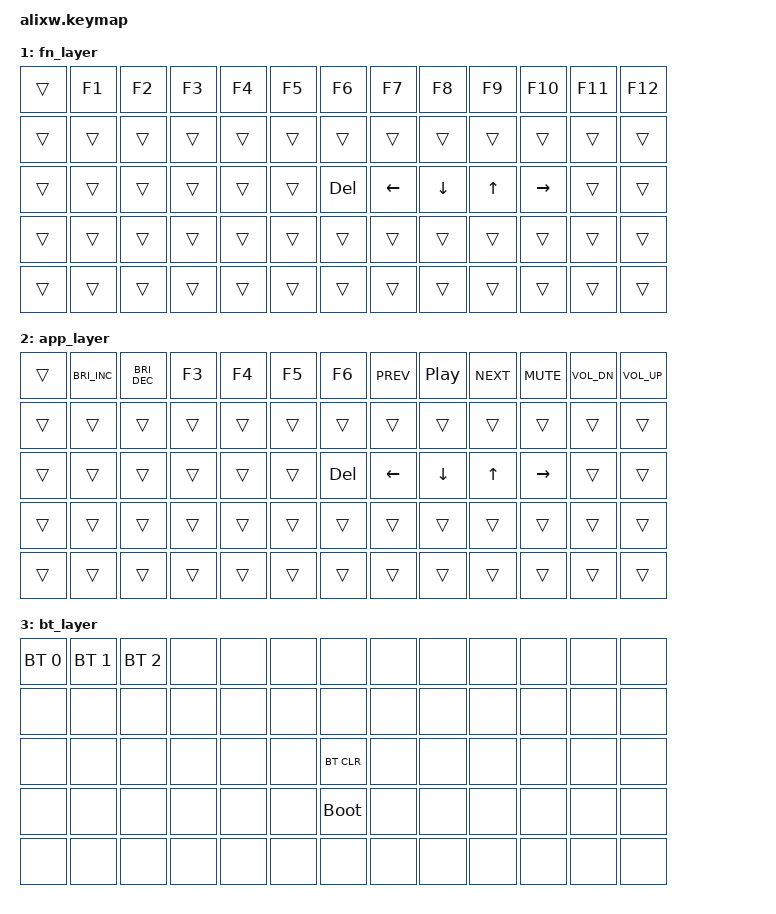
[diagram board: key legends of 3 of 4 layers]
#include <behaviors.dtsi>
#include <dt-bindings/zmk/keys.h>
#include <dt-bindings/zmk/bt.h>

/ {
    keymap {
        compatible = "zmk,keymap";

        default_layer {
            bindings = <
                &kp GRAVE  &kp N1    &kp N2    &kp N3     &kp N4  &kp N5     &kp N6    &kp N7    &kp N8    &kp N9     &kp N0   &kp MINUS  &kp EQUAL
                &kp TAB    &kp Q     &kp W     &kp E      &kp R   &kp T      &kp Y     &kp U     &kp I     &kp O      &kp P    &kp LBKT   &kp RBKT
                &kp CAPS   &kp A     &kp S     &kp D      &kp F   &kp G      &kp BSPC  &kp H     &kp J     &kp K      &kp L    &kp SEMI   &kp SQT
                &kp LSHFT  &kp Z     &kp X     &kp C      &kp V   &kp B      &kp ESC   &kp N     &kp M     &kp COMMA  &kp DOT  &kp SLASH  &kp RSHFT
                &kp LCTRL  &kp LALT  &kp LGUI  &kp SPACE  &mo 2   &kp ENTER  &mo 1     &kp RGUI  &kp RALT  &kp RCTRL  &tog 1   &mo 3      &kp BSLH
            >;
        };

        fn_layer {
            bindings = <
                &trans     &kp F1    &kp F2    &kp F3     &kp F4  &kp F5     &kp F6    &kp F7    &kp F8    &kp F9     &kp F10    &kp F11  &kp F12
                &trans     &trans    &trans    &trans     &trans  &trans     &trans    &trans    &trans    &trans     &trans     &trans   &trans
                &trans     &trans    &trans    &trans     &trans  &trans     &kp DEL   &kp LEFT  &kp DOWN  &kp UP     &kp RIGHT  &trans   &trans
                &trans     &trans    &trans    &trans     &trans  &trans     &trans    &trans    &trans    &trans     &trans     &trans   &trans
                &trans     &trans    &trans    &trans     &trans  &trans     &trans    &trans    &trans    &trans     &trans     &trans   &trans 
            >;
        };

        app_layer {
            bindings = <
                &trans  &kp C_BRI_INC  &kp C_BRI_DEC  &kp F3  &kp F4  &kp F5  &kp F6   &kp C_PREV  &kp C_PP  &kp C_NEXT  &kp K_MUTE  &kp C_VOL_DN  &kp C_VOL_UP
                &trans  &trans         &trans         &trans  &trans  &trans  &trans   &trans      &trans    &trans      &trans      &trans        &trans
                &trans  &trans         &trans         &trans  &trans  &trans  &kp DEL  &kp LEFT    &kp DOWN  &kp UP      &kp RIGHT   &trans        &trans
                &trans  &trans         &trans         &trans  &trans  &trans  &trans   &trans      &trans    &trans      &trans      &trans        &trans
                &trans  &trans         &trans         &trans  &trans  &trans  &trans   &trans      &trans    &trans      &trans      &trans        &trans 
            >;
        };

        bt_layer {
            bindings = <
                &bt BT_SEL 0  &bt BT_SEL 1  &bt BT_SEL 2  &none  &none  &none  &none        &none  &none  &none  &none  &none  &none
                &none         &none         &none         &none  &none  &none  &none        &none  &none  &none  &none  &none  &none
                &none         &none         &none         &none  &none  &none  &bt BT_CLR   &none  &none  &none  &none  &none  &none
                &none         &none         &none         &none  &none  &none  &bootloader  &none  &none  &none  &none  &none  &none
                &none         &none         &none         &none  &none  &none  &none        &none  &none  &none  &none  &none  &none
            >;
        };
    };
};

/ {
    keymap {
        compatible = "zmk,keymap";

        default_layer { // qwert
            display-name = "QWERT";
            bindings = <
                &kp TAB     &kp N1   &kp N2   &kp N3   &kp N4   &trans      &trans  &trans  &trans      &trans
                &kp CAPS    &kp Q    &kp W    &kp E    &kp R    &kp T       &kp Y   &kp U   &kp I       &trans
                &kp LSHIFT  &kp A    &kp S    &kp D    &kp F    &kp G       &kp H   &kp J   &kp K       &kp N1
                &kp LCTRL   &kp Z    &kp X    &kp C    &kp V    &kp B       &kp N   &kp M   &kp DOT     &kp BSPC
                &kp LGUI    &mo 2    &kp SPC  &mo 3    &kp LGUI &trans      &trans    &trans    &trans        &trans
            >;
        };
    };
};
